# RS1xxxx register map
Vendor: Silicon Lab Inc.; Series: ARMCM4; File version: 1.2
CPU: CM4 r1p0, little endian, MPU, FPU, 6 interrupt priority bits
Registers are 32-bit, read-write, reset 0x0 unless marked. A register's access mark holds for its fields unless they carry their own. Offsets are from the block's base; [hi:lo] are bit positions.

## CTS — The capacitive touch sensor (CTS) controller is used to detect the position of the touch from the user on the capacitive touch screen
Base 0x24042C00
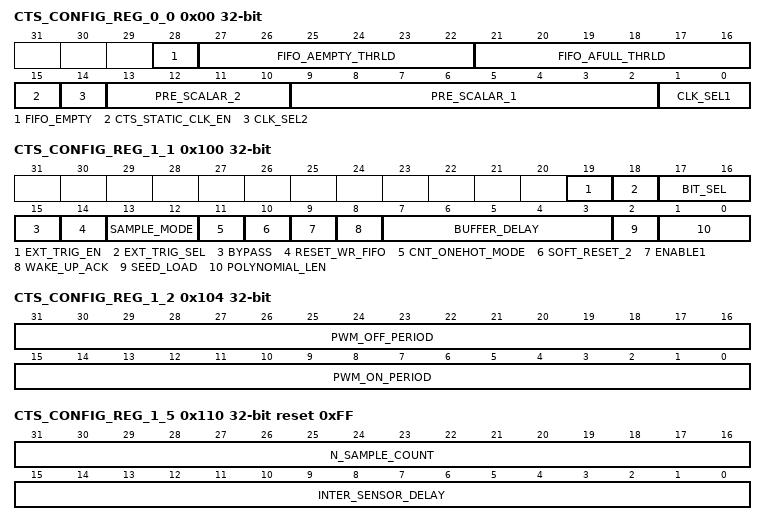
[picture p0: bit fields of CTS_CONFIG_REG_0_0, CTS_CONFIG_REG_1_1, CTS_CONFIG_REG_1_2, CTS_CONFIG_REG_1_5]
0x00 CTS_CONFIG_REG_0_0 — Configuration Register 0_0
  [28] FIFO_EMPTY ro — FIFO empty status bit
  [27:22] FIFO_AEMPTY_THRLD — Threshold for fifo aempty
  [21:16] FIFO_AFULL_THRLD — Threshold for fifo afull
  [15] CTS_STATIC_CLK_EN — Enable static for capacitive touch sensor
    0=disable (Clocks are gated); 1=enable (Clocks are not gated)
  [14] CLK_SEL2 — Mux select for clock_mux_2
  [13:10] PRE_SCALAR_2 — Division factor for clock divider
  [9:2] PRE_SCALAR_1 — Division factor for clock divider
  [1:0] CLK_SEL1 — Mux select for clock_mux_1
0x04 CTS_FIFO_ADDRESS — FIFO Address Register
  [31:0] FIFO — Used for FIFO reads and write operations
0x100 CTS_CONFIG_REG_1_1 — Configuration Register 1_1
  [19] EXT_TRIG_EN — Select bit for NPSS clock or Enable
    0=Enable; 1=Clock (NPSS clock)
  [18] EXT_TRIG_SEL — Select bit for NPSS clock or Enable
  [17:16] BIT_SEL — Selects different set of 12 bits to be stored in FIFO
  [15] BYPASS wo — Bypass signal
    0=Disable (Use Random number generator output bit as input to Non-Overlapping stream generator.); 1=Enable (Bypass the Random number generator output to the Non-overlapping stream generator and to give clock as input to the Non-Overlapping stream generator.)
  [14] RESET_WR_FIFO — Resets the signal fifo_wr_int
    0=Reset; 1=Out_of_reset
  [13:12] SAMPLE_MODE — Select bits for FIFO write and FIFO average
  [11] CNT_ONEHOT_MODE — Continuous or One hot mode
    0=One_hot (disable the cap sensor module); 1=Continuous (enable the cap sensor module)
  [10] SOFT_RESET_2 — Reset the FIFO write and FIFO read occupancy pointers
  [9] ENABLE1 — Enable signal
    0=disable the cap sensor module; 1=enable the cap sensor module
  [8] WAKE_UP_ACK — Ack for wake up interrupt. This is a level signal. To acknowledge wake up , set this bit to one and reset it .
  [7:3] BUFFER_DELAY — Delay of buffer. Delay programmed will be equal to delay in nano seconds. Max delay value is 32.Default delay should be programmed before using Capacitive touch sensor module.
  [2] SEED_LOAD — Seed of polynomial
    0=disable (loading of seed is not allowed); 1=enable (to load the seed)
  [1:0] POLYNOMIAL_LEN — Length of polynomial
0x104 CTS_CONFIG_REG_1_2 — Configuration Register 1_2
  [31:16] PWM_OFF_PERIOD, [15:0] PWM_ON_PERIOD
0x108 CTS_CONFIG_REG_1_3 — Configuration Register 1_3
  [31:0] PRS_SEED — Pseudo random generator (PRS) seed value
0x10C CTS_CONFIG_REG_1_4 — Configuration Register 1_4
  [31:0] PRS_POLY — Polynomial programming register for PRS generator
0x110 CTS_CONFIG_REG_1_5 reset 0xFF — Configuration Register 1_5
  [31:16] N_SAMPLE_COUNT — Number of repetitions of sensor scan
  [15:0] INTER_SENSOR_DELAY — Inter-sensor scan delay value
0x114 CTS_CONFIG_REG_1_6 — Configuration Register 1_6
  [31:0] SENSOR_CFG — Register of scan controller containing the programmed bit map
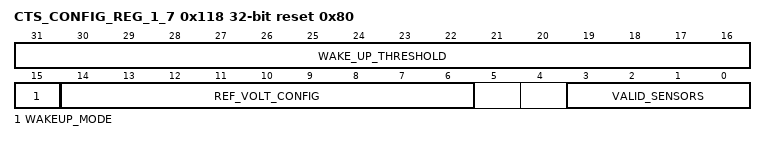
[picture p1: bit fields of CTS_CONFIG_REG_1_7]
0x118 CTS_CONFIG_REG_1_7 reset 0x80 — Configuration Register 1_7
  [31:16] WAKE_UP_THRESHOLD
  [15] WAKEUP_MODE — Select bit for high/low mode.
    1=Greater_Than (Wakeup if count is greater than threshold); 0=Less_Than (Wakeup if count is lesser than threshold)
  [14:6] REF_VOLT_CONFIG — This is given as an input voltage to analog model as comparator reference voltage.
  [3:0] VALID_SENSORS — Value of number of sensors valid in the bit map
0x11C CTS_CONFIG_REG_1_8 ro — Configuration Register 1_8
  [31:0] PRS_STATE — Current state of PRS
0x120 CTS_CONFIG_REG_1_9 — Configuration Register 1_9
  [9:0] TRIG_DIV — Allows one pulse for every 'trig_div' no. of pulses of 1 ms clock
